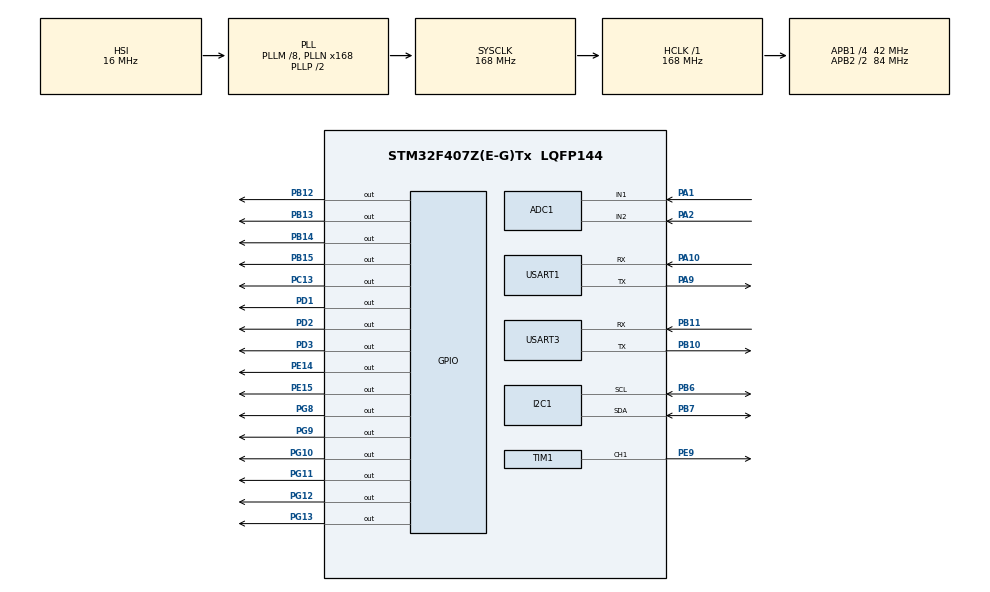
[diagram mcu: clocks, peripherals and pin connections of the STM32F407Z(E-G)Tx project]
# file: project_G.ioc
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ADC1.Channel-1\#ChannelRegularConversion=ADC_CHANNEL_1
ADC1.ContinuousConvMode=ENABLE
ADC1.NbrOfConversion=1
ADC1.NbrOfConversionFlag=1
ADC1.Rank-1\#ChannelRegularConversion=1
ADC1.SamplingTime-1\#ChannelRegularConversion=ADC_SAMPLETIME_3CYCLES
ADC1.master=1
Dma.ADC1.0.Direction=DMA_PERIPH_TO_MEMORY
Dma.ADC1.0.FIFOMode=DMA_FIFOMODE_DISABLE
Dma.ADC1.0.Instance=DMA2_Stream0
Dma.ADC1.0.MemDataAlignment=DMA_MDATAALIGN_HALFWORD
Dma.ADC1.0.MemInc=DMA_MINC_ENABLE
Dma.ADC1.0.Mode=DMA_NORMAL
Dma.ADC1.0.PeriphDataAlignment=DMA_PDATAALIGN_HALFWORD
Dma.ADC1.0.PeriphInc=DMA_PINC_DISABLE
Dma.ADC1.0.Priority=DMA_PRIORITY_LOW
Dma.Request0=ADC1
Dma.Request1=USART1_RX
Dma.USART1_RX.1.Direction=DMA_PERIPH_TO_MEMORY
Dma.USART1_RX.1.FIFOMode=DMA_FIFOMODE_DISABLE
Dma.USART1_RX.1.Instance=DMA2_Stream2
Dma.USART1_RX.1.MemDataAlignment=DMA_MDATAALIGN_BYTE
Dma.USART1_RX.1.MemInc=DMA_MINC_ENABLE
Dma.USART1_RX.1.Mode=DMA_NORMAL
Dma.USART1_RX.1.PeriphDataAlignment=DMA_PDATAALIGN_BYTE
Dma.USART1_RX.1.PeriphInc=DMA_PINC_DISABLE
Dma.USART1_RX.1.Priority=DMA_PRIORITY_LOW
I2C1.I2C_Mode=I2C_Standard
Mcu.Family=STM32F4
Mcu.Name=STM32F407Z(E-G)Tx
Mcu.Package=LQFP144
NVIC.DMA2_Stream0_IRQn=true\:0\:0\:false\:false\:true\:false\:true\:true
NVIC.DMA2_Stream2_IRQn=true\:0\:0\:false\:false\:true\:false\:true\:true
NVIC.PriorityGroup=NVIC_PRIORITYGROUP_4
NVIC.USART1_IRQn=true\:0\:0\:false\:false\:true\:true\:true\:true
PA1.Signal=ADCx_IN1
PA10.Mode=Asynchronous
PA10.Signal=USART1_RX
PA13.Mode=Serial_Wire
PA13.Signal=SYS_JTMS-SWDIO
PA14.Mode=Serial_Wire
PA14.Signal=SYS_JTCK-SWCLK
PA2.Signal=ADCx_IN2
PA9.Mode=Asynchronous
PA9.Signal=USART1_TX
PB10.Mode=Asynchronous
PB10.Signal=USART3_TX
PB11.Mode=Asynchronous
PB11.Signal=USART3_RX
PB12.GPIO_ModeDefaultOutputPP=GPIO_MODE_OUTPUT_PP
PB12.GPIO_PuPd=GPIO_NOPULL
PB12.GPIO_Speed=GPIO_SPEED_FREQ_HIGH
PB12.Signal=GPIO_Output
PB13.GPIO_ModeDefaultOutputPP=GPIO_MODE_OUTPUT_PP
PB13.GPIO_PuPd=GPIO_NOPULL
PB13.GPIO_Speed=GPIO_SPEED_FREQ_HIGH
PB13.Signal=GPIO_Output
PB14.GPIO_ModeDefaultOutputPP=GPIO_MODE_OUTPUT_PP
PB14.GPIO_PuPd=GPIO_NOPULL
PB14.GPIO_Speed=GPIO_SPEED_FREQ_HIGH
PB14.Signal=GPIO_Output
PB15.GPIO_ModeDefaultOutputPP=GPIO_MODE_OUTPUT_PP
PB15.GPIO_PuPd=GPIO_NOPULL
PB15.GPIO_Speed=GPIO_SPEED_FREQ_HIGH
PB15.Signal=GPIO_Output
PB6.GPIO_Pu=GPIO_PULLUP
PB6.Mode=I2C
PB6.Signal=I2C1_SCL
PB7.GPIO_Pu=GPIO_PULLUP
PB7.Mode=I2C
PB7.Signal=I2C1_SDA
PC13-ANTI_TAMP.Signal=GPIO_Output
PD1.Signal=GPIO_Output
PD2.Signal=GPIO_Output
PD3.Signal=GPIO_Output
PE14.GPIO_Speed=GPIO_SPEED_FREQ_HIGH
PE14.PinState=GPIO_PIN_SET
PE14.Signal=GPIO_Output
PE15.GPIO_Speed=GPIO_SPEED_FREQ_HIGH
PE15.PinState=GPIO_PIN_SET
PE15.Signal=GPIO_Output
PE9.GPIO_Speed=GPIO_SPEED_FREQ_VERY_HIGH
PE9.Signal=S_TIM1_CH1
PG10.GPIO_Speed=GPIO_SPEED_FREQ_HIGH
PG10.Signal=GPIO_Output
PG11.GPIO_Speed=GPIO_SPEED_FREQ_HIGH
PG11.Signal=GPIO_Output
PG12.GPIO_Speed=GPIO_SPEED_FREQ_HIGH
PG12.Signal=GPIO_Output
PG13.GPIO_Speed=GPIO_SPEED_FREQ_HIGH
PG13.Signal=GPIO_Output
PG8.GPIO_Speed=GPIO_SPEED_FREQ_HIGH
PG8.Signal=GPIO_Output
PG9.GPIO_Speed=GPIO_SPEED_FREQ_HIGH
PG9.Signal=GPIO_Output
PH0-OSC_IN.Mode=HSE-External-Oscillator
PH0-OSC_IN.Signal=RCC_OSC_IN
PH1-OSC_OUT.Mode=HSE-External-Oscillator
PH1-OSC_OUT.Signal=RCC_OSC_OUT
ProjectManager.HeapSize=0x200
ProjectManager.StackSize=0x400
ProjectManager.TargetToolchain=MDK-ARM V5.32
RCC.48MHZClocksFreq_Value=84000000
RCC.AHBFreq_Value=168000000
RCC.APB1CLKDivider=RCC_HCLK_DIV4
RCC.APB1Freq_Value=42000000
RCC.APB1TimFreq_Value=84000000
RCC.APB2CLKDivider=RCC_HCLK_DIV2
RCC.APB2Freq_Value=84000000
RCC.APB2TimFreq_Value=168000000
RCC.CortexFreq_Value=168000000
RCC.HCLKFreq_Value=168000000
RCC.HSE_VALUE=25000000
RCC.HSI_VALUE=16000000
RCC.LSE_VALUE=32768
RCC.PLLM=8
RCC.PLLN=168
RCC.SYSCLKFreq_VALUE=168000000
RCC.SYSCLKSource=RCC_SYSCLKSOURCE_PLLCLK
RCC.VCOOutputFreq_Value=336000000
SH.ADCx_IN1.0=ADC1_IN1,IN1
SH.ADCx_IN2.0=ADC1_IN2,IN2
SH.S_TIM1_CH1.0=TIM1_CH1,PWM Generation1 CH1
STMicroelectronics.X-CUBE-ALGOBUILD.1.4.0.LibraryCcDSPOoLibraryJjDSPOoLibrary=true
TIM1.AutoReloadPreload=TIM_AUTORELOAD_PRELOAD_ENABLE
TIM1.Channel-PWM\ Generation1\ CH1=TIM_CHANNEL_1
TIM1.Pulse-PWM\ Generation1\ CH1=50
USART1.VirtualMode=VM_ASYNC
USART3.VirtualMode=VM_ASYNC
VP_STMicroelectronics.X-CUBE-ALGOBUILD_VS_DSPOoLibraryJjLibrary_1.4.0_1.4.0.Mode=DSPOoLibraryJjLibrary
VP_TIM1_VS_ClockSourceINT.Mode=Internal
board=custom

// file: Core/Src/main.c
/* USER CODE BEGIN Header */
/**
 ******************************************************************************
 * @file           : main.c
 * @brief          : Main program body
 ******************************************************************************
 * @attention
 *
 * Copyright (c) 2025 STMicroelectronics.
 * All rights reserved.
 *
 * This software is licensed under terms that can be found in the LICENSE file
 * in the root directory of this software component.
 * If no LICENSE file comes with this software, it is provided AS-IS.
 *
 ******************************************************************************
 */
/* USER CODE END Header */
#include "main.h"
#include "adc.h"
#include "dma.h"
#include "i2c.h"
#include "tim.h"
#include "usart.h"
#include "gpio.h"

/* USER CODE BEGIN Includes */
#include "header.h"
/* USER CODE END Includes */

void SystemClock_Config(void);

int main(void)
{

  /* MCU Configuration--------------------------------------------------------*/

  /* Reset of all peripherals, Initializes the Flash interface and the Systick. */
  HAL_Init();

  /* Configure the system clock */
  SystemClock_Config();

  /* Initialize all configured peripherals */
  MX_GPIO_Init();
  MX_DMA_Init();
  MX_ADC1_Init();
  MX_USART1_UART_Init();
  MX_USART3_UART_Init();
  MX_TIM1_Init();
  MX_I2C1_Init();
  /* USER CODE BEGIN 2 */
  // HAL_GPIO_WritePin(GPIOB,GPIO_PIN_8,GPIO_PIN_SET);
  LED_Debug(1);
  HAL_Delay(500);
  //------------------------------------------------------
  Func_Init();
  HMI_Process_Init();
  MAX262_Init();
  Debug_printf("System Start:%d\r\n", 1);
  //------------------------------------------------------
  LED_Debug(0);
  HAL_Delay(1000);
  LED_Debug(1);
  HAL_Delay(500);
  LED_Debug(0);
  /* 测试DDS模块最大输出幅值*/

  // AD9833_AmpSet(255);
  // AD9833_WaveSeting(1000.0,0,SIN_WAVE,0);

  /* USER CODE END 2 */

  /* Infinite loop */
  /* USER CODE BEGIN WHILE */
  while (1)
  {
    HMI_Process_Task_Poll();
    /* USER CODE END WHILE */

  }
}

void SystemClock_Config(void)
{
  RCC_OscInitTypeDef RCC_OscInitStruct = {0};
  RCC_ClkInitTypeDef RCC_ClkInitStruct = {0};

  /** Configure the main internal regulator output voltage
  */
  __HAL_RCC_PWR_CLK_ENABLE();
  __HAL_PWR_VOLTAGESCALING_CONFIG(PWR_REGULATOR_VOLTAGE_SCALE1);

  /** Initializes the RCC Oscillators according to the specified parameters
  * in the RCC_OscInitTypeDef structure.
  */
  RCC_OscInitStruct.OscillatorType = RCC_OSCILLATORTYPE_HSI;
  RCC_OscInitStruct.HSIState = RCC_HSI_ON;
  RCC_OscInitStruct.HSICalibrationValue = RCC_HSICALIBRATION_DEFAULT;
  RCC_OscInitStruct.PLL.PLLState = RCC_PLL_ON;
  RCC_OscInitStruct.PLL.PLLSource = RCC_PLLSOURCE_HSI;
  RCC_OscInitStruct.PLL.PLLM = 8;
  RCC_OscInitStruct.PLL.PLLN = 168;
  RCC_OscInitStruct.PLL.PLLP = RCC_PLLP_DIV2;
  RCC_OscInitStruct.PLL.PLLQ = 4;
  if (HAL_RCC_OscConfig(&RCC_OscInitStruct) != HAL_OK)
  {
    Error_Handler();
  }

  /** Initializes the CPU, AHB and APB buses clocks
  */
  RCC_ClkInitStruct.ClockType = RCC_CLOCKTYPE_HCLK|RCC_CLOCKTYPE_SYSCLK
                              |RCC_CLOCKTYPE_PCLK1|RCC_CLOCKTYPE_PCLK2;
  RCC_ClkInitStruct.SYSCLKSource = RCC_SYSCLKSOURCE_PLLCLK;
  RCC_ClkInitStruct.AHBCLKDivider = RCC_SYSCLK_DIV1;
  RCC_ClkInitStruct.APB1CLKDivider = RCC_HCLK_DIV4;
  RCC_ClkInitStruct.APB2CLKDivider = RCC_HCLK_DIV2;

  if (HAL_RCC_ClockConfig(&RCC_ClkInitStruct, FLASH_LATENCY_5) != HAL_OK)
  {
    Error_Handler();
  }
}

void Error_Handler(void)
{
  __disable_irq();
  while (1)
  {
  }
}
